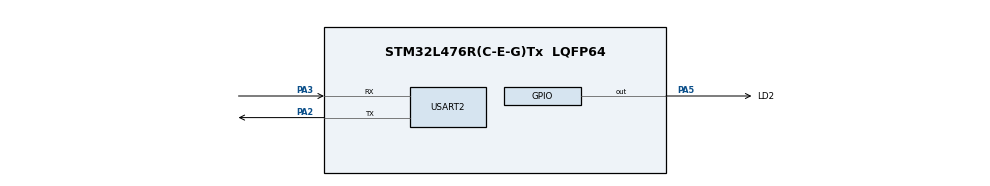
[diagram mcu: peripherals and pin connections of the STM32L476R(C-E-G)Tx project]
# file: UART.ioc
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Mcu.Family=STM32L4
Mcu.Name=STM32L476R(C-E-G)Tx
Mcu.Package=LQFP64
NVIC.PriorityGroup=NVIC_PRIORITYGROUP_4
PA13\ (JTMS-SWDIO).Mode=Serial_Wire
PA13\ (JTMS-SWDIO).Signal=SYS_JTMS-SWDIO
PA14\ (JTCK-SWCLK).Mode=Serial_Wire
PA14\ (JTCK-SWCLK).Signal=SYS_JTCK-SWCLK
PA2.Mode=Asynchronous
PA2.Signal=USART2_TX
PA3.Mode=Asynchronous
PA3.Signal=USART2_RX
PA5.GPIO_Label=LD2
PA5.Signal=GPIO_Output
ProjectManager.HeapSize=0x200
ProjectManager.StackSize=0x400
ProjectManager.TargetToolchain=STM32CubeIDE
RCC.HSE_VALUE=8000000
RCC.HSI_VALUE=16000000
RCC.LSE_VALUE=32768
RCC.MSI_VALUE=4000000
RCC.VCOOutputFreq_Value=32000000
USART2.OverrunDisableParam=ADVFEATURE_OVERRUN_DISABLE
USART2.VirtualMode-Asynchronous=VM_ASYNC
board=custom

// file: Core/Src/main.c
/* USER CODE BEGIN Header */
/**
  ******************************************************************************
  * @file           : main.c
  * @brief          : Main program body
  ******************************************************************************
  * @attention
  *
  * Copyright (c) 2022 STMicroelectronics.
  * All rights reserved.
  *
  * This software is licensed under terms that can be found in the LICENSE file
  * in the root directory of this software component.
  * If no LICENSE file comes with this software, it is provided AS-IS.
  *
  ******************************************************************************
  */
/* USER CODE END Header */
#include "main.h"

/* USER CODE BEGIN Includes */
#include <string.h>
#include <stdio.h>
/* USER CODE END Includes */

/* USER CODE BEGIN PD */
#define LINE_MAX_LENGTH 80
/* USER CODE END PD */

UART_HandleTypeDef huart2;

void SystemClock_Config(void);
static void MX_GPIO_Init(void);
static void MX_USART2_UART_Init(void);

/* USER CODE BEGIN 0 */

static char line_buffer[LINE_MAX_LENGTH + 1];
static uint32_t line_length;

void line_append(uint8_t value)
{
	if ( (value == '\r') || (value ==  '\n') )
	{
		if (line_length > 0)
		{
			line_buffer[line_length] = '\0';

			if ( strcmp(line_buffer, "on") == 0)
			{
				HAL_GPIO_WritePin(LD2_GPIO_Port, LD2_Pin, GPIO_PIN_SET);
			}
			else if ( strcmp(line_buffer, "off") == 0)
			{
				HAL_GPIO_WritePin(LD2_GPIO_Port, LD2_Pin, GPIO_PIN_RESET);
			}
			else
			{
				printf("Unknown command:\n");
			}
			printf("Received: %s\n", line_buffer);

			line_length = 0;
		}
	}
	else
	{
		if (line_length >= LINE_MAX_LENGTH)
		{
			line_length = 0;
			printf("Too long sentence - maximum is 80 characters\n");
		}
		line_buffer[line_length++] = value;
	}
}

int __io_putchar(int ch)
{
	if ( ch=='\n')
	{
		uint8_t ch2 = '\r';
		HAL_UART_Transmit(&huart2, (uint8_t*)&ch2, 1, HAL_MAX_DELAY);
	}
	HAL_UART_Transmit(&huart2, (uint8_t*)&ch, 1, HAL_MAX_DELAY);
	return 1;
}

/* USER CODE END 0 */

int main(void)
{

  /* MCU Configuration--------------------------------------------------------*/

  /* Reset of all peripherals, Initializes the Flash interface and the Systick. */
  HAL_Init();

  /* Configure the system clock */
  SystemClock_Config();

  /* Initialize all configured peripherals */
  MX_GPIO_Init();
  MX_USART2_UART_Init();
  /* USER CODE BEGIN 2 */

printf("Hello world!\n");

printf("Hello world! 1");
printf("Hello world! 2");
printf("Hello world! 3");
fflush(stdout);

float pi = 3.14f;
printf("Number pi is: %f\n", pi);

  /* USER CODE END 2 */

  /* Infinite loop */
  /* USER CODE BEGIN WHILE */
  while (1)
  {
	  uint8_t value;
	  if (HAL_UART_Receive(&huart2, &value, 1, 0) == HAL_OK)
	  {
		  line_append(value);
	  }
    /* USER CODE END WHILE */

  }
}

void SystemClock_Config(void)
{
  RCC_OscInitTypeDef RCC_OscInitStruct = {0};
  RCC_ClkInitTypeDef RCC_ClkInitStruct = {0};

  /** Configure the main internal regulator output voltage
  */
  if (HAL_PWREx_ControlVoltageScaling(PWR_REGULATOR_VOLTAGE_SCALE1) != HAL_OK)
  {
    Error_Handler();
  }

  /** Initializes the RCC Oscillators according to the specified parameters
  * in the RCC_OscInitTypeDef structure.
  */
  RCC_OscInitStruct.OscillatorType = RCC_OSCILLATORTYPE_MSI;
  RCC_OscInitStruct.MSIState = RCC_MSI_ON;
  RCC_OscInitStruct.MSICalibrationValue = 0;
  RCC_OscInitStruct.MSIClockRange = RCC_MSIRANGE_6;
  RCC_OscInitStruct.PLL.PLLState = RCC_PLL_NONE;
  if (HAL_RCC_OscConfig(&RCC_OscInitStruct) != HAL_OK)
  {
    Error_Handler();
  }

  /** Initializes the CPU, AHB and APB buses clocks
  */
  RCC_ClkInitStruct.ClockType = RCC_CLOCKTYPE_HCLK|RCC_CLOCKTYPE_SYSCLK
                              |RCC_CLOCKTYPE_PCLK1|RCC_CLOCKTYPE_PCLK2;
  RCC_ClkInitStruct.SYSCLKSource = RCC_SYSCLKSOURCE_MSI;
  RCC_ClkInitStruct.AHBCLKDivider = RCC_SYSCLK_DIV1;
  RCC_ClkInitStruct.APB1CLKDivider = RCC_HCLK_DIV1;
  RCC_ClkInitStruct.APB2CLKDivider = RCC_HCLK_DIV1;

  if (HAL_RCC_ClockConfig(&RCC_ClkInitStruct, FLASH_LATENCY_0) != HAL_OK)
  {
    Error_Handler();
  }
}

static void MX_USART2_UART_Init(void)
{

  huart2.Instance = USART2;
  huart2.Init.BaudRate = 115200;
  huart2.Init.WordLength = UART_WORDLENGTH_8B;
  huart2.Init.StopBits = UART_STOPBITS_1;
  huart2.Init.Parity = UART_PARITY_NONE;
  huart2.Init.Mode = UART_MODE_TX_RX;
  huart2.Init.HwFlowCtl = UART_HWCONTROL_NONE;
  huart2.Init.OverSampling = UART_OVERSAMPLING_16;
  huart2.Init.OneBitSampling = UART_ONE_BIT_SAMPLE_DISABLE;
  huart2.AdvancedInit.AdvFeatureInit = UART_ADVFEATURE_RXOVERRUNDISABLE_INIT;
  huart2.AdvancedInit.OverrunDisable = UART_ADVFEATURE_OVERRUN_DISABLE;
  if (HAL_UART_Init(&huart2) != HAL_OK)
  {
    Error_Handler();
  }

}

static void MX_GPIO_Init(void)
{
  GPIO_InitTypeDef GPIO_InitStruct = {0};

  /* GPIO Ports Clock Enable */
  __HAL_RCC_GPIOA_CLK_ENABLE();

  /*Configure GPIO pin Output Level */
  HAL_GPIO_WritePin(LD2_GPIO_Port, LD2_Pin, GPIO_PIN_RESET);

  /*Configure GPIO pin : LD2_Pin */
  GPIO_InitStruct.Pin = LD2_Pin;
  GPIO_InitStruct.Mode = GPIO_MODE_OUTPUT_PP;
  GPIO_InitStruct.Pull = GPIO_NOPULL;
  GPIO_InitStruct.Speed = GPIO_SPEED_FREQ_LOW;
  HAL_GPIO_Init(LD2_GPIO_Port, &GPIO_InitStruct);

}

void Error_Handler(void)
{
  __disable_irq();
  while (1)
  {
  }
}
